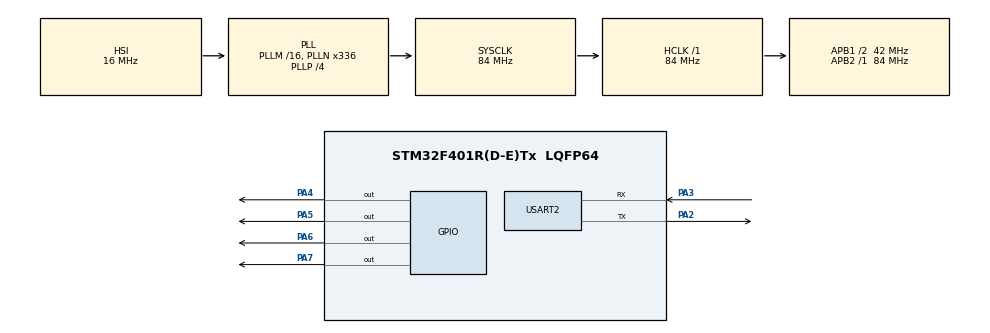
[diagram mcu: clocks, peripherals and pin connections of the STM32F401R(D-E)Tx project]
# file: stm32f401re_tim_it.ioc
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Mcu.Family=STM32F4
Mcu.Name=STM32F401R(D-E)Tx
Mcu.Package=LQFP64
NVIC.PriorityGroup=NVIC_PRIORITYGROUP_4
NVIC.TIM3_IRQn=true\:0\:0\:false\:false\:true\:true\:true\:true
NVIC.TIM4_IRQn=true\:0\:0\:false\:false\:true\:true\:true\:true
NVIC.TIM5_IRQn=true\:0\:0\:false\:false\:true\:true\:true\:true
PA2.Mode=Asynchronous
PA2.Signal=USART2_TX
PA3.Mode=Asynchronous
PA3.Signal=USART2_RX
PA4.Signal=GPIO_Output
PA5.Signal=GPIO_Output
PA6.Signal=GPIO_Output
PA7.Signal=GPIO_Output
ProjectManager.HeapSize=0x200
ProjectManager.StackSize=0x400
ProjectManager.TargetToolchain=STM32CubeIDE
RCC.48MHZClocksFreq_Value=48000000
RCC.AHBFreq_Value=84000000
RCC.APB1CLKDivider=RCC_HCLK_DIV2
RCC.APB1Freq_Value=42000000
RCC.APB1TimFreq_Value=84000000
RCC.APB2Freq_Value=84000000
RCC.APB2TimFreq_Value=84000000
RCC.CortexFreq_Value=84000000
RCC.HCLKFreq_Value=84000000
RCC.HSE_VALUE=8000000
RCC.HSI_VALUE=16000000
RCC.LSE_VALUE=32768
RCC.PLLN=336
RCC.PLLP=RCC_PLLP_DIV4
RCC.PLLQ=7
RCC.SYSCLKFreq_VALUE=84000000
RCC.SYSCLKSource=RCC_SYSCLKSOURCE_PLLCLK
RCC.VCOOutputFreq_Value=336000000
TIM3.Period=2000-1
TIM3.Prescaler=8400
TIM4.Period=5000-1
TIM4.Prescaler=8400-1
TIM5.Period=8000-1
TIM5.Prescaler=8400-1
USART2.VirtualMode=VM_ASYNC
VP_TIM3_VS_ClockSourceINT.Mode=Internal
VP_TIM4_VS_ClockSourceINT.Mode=Internal
VP_TIM5_VS_ClockSourceINT.Mode=Internal
board=NUCLEO-F401RE

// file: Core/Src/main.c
/* USER CODE BEGIN Header */
/**
  ******************************************************************************
  * @file           : main.c
  * @brief          : Main program body
  ******************************************************************************
  * @attention
  *
  * Copyright (c) 2025 STMicroelectronics.
  * All rights reserved.
  *
  * This software is licensed under terms that can be found in the LICENSE file
  * in the root directory of this software component.
  * If no LICENSE file comes with this software, it is provided AS-IS.
  *
  ******************************************************************************
  */
/* USER CODE END Header */
#include "main.h"

TIM_HandleTypeDef htim3;
TIM_HandleTypeDef htim4;
TIM_HandleTypeDef htim5;

UART_HandleTypeDef huart2;

void SystemClock_Config(void);
static void MX_GPIO_Init(void);
static void MX_TIM3_Init(void);
static void MX_TIM4_Init(void);
static void MX_TIM5_Init(void);
static void MX_USART2_UART_Init(void);

int main(void)
{

  /* MCU Configuration--------------------------------------------------------*/

  /* Reset of all peripherals, Initializes the Flash interface and the Systick. */
  HAL_Init();

  /* Configure the system clock */
  SystemClock_Config();

  /* Initialize all configured peripherals */
  MX_GPIO_Init();
  MX_TIM3_Init();
  MX_TIM4_Init();
  MX_TIM5_Init();
  MX_USART2_UART_Init();
  /* USER CODE BEGIN 2 */
  HAL_TIM_Base_Start_IT(&htim3);
  HAL_TIM_Base_Start_IT(&htim4);
  HAL_TIM_Base_Start_IT(&htim5);

  /* USER CODE END 2 */
HAL_UART_Transmit(&huart2, "DEVICE ON\n",20,20);
  /* Infinite loop */
  while (1)
  {
	//  HAL_UART_Transmit(&huart2, "DEVICE ON\n",20,20);

  }
}

void SystemClock_Config(void)
{
  RCC_OscInitTypeDef RCC_OscInitStruct = {0};
  RCC_ClkInitTypeDef RCC_ClkInitStruct = {0};

  /** Configure the main internal regulator output voltage
  */
  __HAL_RCC_PWR_CLK_ENABLE();
  __HAL_PWR_VOLTAGESCALING_CONFIG(PWR_REGULATOR_VOLTAGE_SCALE2);

  /** Initializes the RCC Oscillators according to the specified parameters
  * in the RCC_OscInitTypeDef structure.
  */
  RCC_OscInitStruct.OscillatorType = RCC_OSCILLATORTYPE_HSI;
  RCC_OscInitStruct.HSIState = RCC_HSI_ON;
  RCC_OscInitStruct.HSICalibrationValue = RCC_HSICALIBRATION_DEFAULT;
  RCC_OscInitStruct.PLL.PLLState = RCC_PLL_ON;
  RCC_OscInitStruct.PLL.PLLSource = RCC_PLLSOURCE_HSI;
  RCC_OscInitStruct.PLL.PLLM = 16;
  RCC_OscInitStruct.PLL.PLLN = 336;
  RCC_OscInitStruct.PLL.PLLP = RCC_PLLP_DIV4;
  RCC_OscInitStruct.PLL.PLLQ = 7;
  if (HAL_RCC_OscConfig(&RCC_OscInitStruct) != HAL_OK)
  {
    Error_Handler();
  }

  /** Initializes the CPU, AHB and APB buses clocks
  */
  RCC_ClkInitStruct.ClockType = RCC_CLOCKTYPE_HCLK|RCC_CLOCKTYPE_SYSCLK
                              |RCC_CLOCKTYPE_PCLK1|RCC_CLOCKTYPE_PCLK2;
  RCC_ClkInitStruct.SYSCLKSource = RCC_SYSCLKSOURCE_PLLCLK;
  RCC_ClkInitStruct.AHBCLKDivider = RCC_SYSCLK_DIV1;
  RCC_ClkInitStruct.APB1CLKDivider = RCC_HCLK_DIV2;
  RCC_ClkInitStruct.APB2CLKDivider = RCC_HCLK_DIV1;

  if (HAL_RCC_ClockConfig(&RCC_ClkInitStruct, FLASH_LATENCY_2) != HAL_OK)
  {
    Error_Handler();
  }
}

static void MX_TIM3_Init(void)
{

  TIM_ClockConfigTypeDef sClockSourceConfig = {0};
  TIM_MasterConfigTypeDef sMasterConfig = {0};

  htim3.Instance = TIM3;
  htim3.Init.Prescaler = 8400-1;
  htim3.Init.CounterMode = TIM_COUNTERMODE_UP;
  htim3.Init.Period = 2000-1;
  htim3.Init.ClockDivision = TIM_CLOCKDIVISION_DIV1;
  htim3.Init.AutoReloadPreload = TIM_AUTORELOAD_PRELOAD_DISABLE;
  if (HAL_TIM_Base_Init(&htim3) != HAL_OK)
  {
    Error_Handler();
  }
  sClockSourceConfig.ClockSource = TIM_CLOCKSOURCE_INTERNAL;
  if (HAL_TIM_ConfigClockSource(&htim3, &sClockSourceConfig) != HAL_OK)
  {
    Error_Handler();
  }
  sMasterConfig.MasterOutputTrigger = TIM_TRGO_RESET;
  sMasterConfig.MasterSlaveMode = TIM_MASTERSLAVEMODE_DISABLE;
  if (HAL_TIMEx_MasterConfigSynchronization(&htim3, &sMasterConfig) != HAL_OK)
  {
    Error_Handler();
  }

}

static void MX_TIM4_Init(void)
{

  TIM_ClockConfigTypeDef sClockSourceConfig = {0};
  TIM_MasterConfigTypeDef sMasterConfig = {0};

  htim4.Instance = TIM4;
  htim4.Init.Prescaler = 8400-1;
  htim4.Init.CounterMode = TIM_COUNTERMODE_UP;
  htim4.Init.Period = 5000-1;
  htim4.Init.ClockDivision = TIM_CLOCKDIVISION_DIV1;
  htim4.Init.AutoReloadPreload = TIM_AUTORELOAD_PRELOAD_DISABLE;
  if (HAL_TIM_Base_Init(&htim4) != HAL_OK)
  {
    Error_Handler();
  }
  sClockSourceConfig.ClockSource = TIM_CLOCKSOURCE_INTERNAL;
  if (HAL_TIM_ConfigClockSource(&htim4, &sClockSourceConfig) != HAL_OK)
  {
    Error_Handler();
  }
  sMasterConfig.MasterOutputTrigger = TIM_TRGO_RESET;
  sMasterConfig.MasterSlaveMode = TIM_MASTERSLAVEMODE_DISABLE;
  if (HAL_TIMEx_MasterConfigSynchronization(&htim4, &sMasterConfig) != HAL_OK)
  {
    Error_Handler();
  }

}

static void MX_TIM5_Init(void)
{

  TIM_ClockConfigTypeDef sClockSourceConfig = {0};
  TIM_MasterConfigTypeDef sMasterConfig = {0};

  htim5.Instance = TIM5;
  htim5.Init.Prescaler = 8400-1;
  htim5.Init.CounterMode = TIM_COUNTERMODE_UP;
  htim5.Init.Period = 8000-1;
  htim5.Init.ClockDivision = TIM_CLOCKDIVISION_DIV1;
  htim5.Init.AutoReloadPreload = TIM_AUTORELOAD_PRELOAD_DISABLE;
  if (HAL_TIM_Base_Init(&htim5) != HAL_OK)
  {
    Error_Handler();
  }
  sClockSourceConfig.ClockSource = TIM_CLOCKSOURCE_INTERNAL;
  if (HAL_TIM_ConfigClockSource(&htim5, &sClockSourceConfig) != HAL_OK)
  {
    Error_Handler();
  }
  sMasterConfig.MasterOutputTrigger = TIM_TRGO_RESET;
  sMasterConfig.MasterSlaveMode = TIM_MASTERSLAVEMODE_DISABLE;
  if (HAL_TIMEx_MasterConfigSynchronization(&htim5, &sMasterConfig) != HAL_OK)
  {
    Error_Handler();
  }

}

static void MX_USART2_UART_Init(void)
{

  huart2.Instance = USART2;
  huart2.Init.BaudRate = 115200;
  huart2.Init.WordLength = UART_WORDLENGTH_8B;
  huart2.Init.StopBits = UART_STOPBITS_1;
  huart2.Init.Parity = UART_PARITY_NONE;
  huart2.Init.Mode = UART_MODE_TX_RX;
  huart2.Init.HwFlowCtl = UART_HWCONTROL_NONE;
  huart2.Init.OverSampling = UART_OVERSAMPLING_16;
  if (HAL_UART_Init(&huart2) != HAL_OK)
  {
    Error_Handler();
  }

}

static void MX_GPIO_Init(void)
{
  GPIO_InitTypeDef GPIO_InitStruct = {0};

  /* GPIO Ports Clock Enable */
  __HAL_RCC_GPIOA_CLK_ENABLE();

  /*Configure GPIO pin Output Level */
  HAL_GPIO_WritePin(GPIOA, GPIO_PIN_4|GPIO_PIN_5|GPIO_PIN_6|GPIO_PIN_7, GPIO_PIN_RESET);

  /*Configure GPIO pins : PA4 PA5 PA6 PA7 */
  GPIO_InitStruct.Pin = GPIO_PIN_4|GPIO_PIN_5|GPIO_PIN_6|GPIO_PIN_7;
  GPIO_InitStruct.Mode = GPIO_MODE_OUTPUT_PP;
  GPIO_InitStruct.Pull = GPIO_NOPULL;
  GPIO_InitStruct.Speed = GPIO_SPEED_FREQ_LOW;
  HAL_GPIO_Init(GPIOA, &GPIO_InitStruct);

}

/* USER CODE BEGIN 4 */
void HAL_TIM_PeriodElapsedCallback(TIM_HandleTypeDef *htim)
{
  /* Prevent unused argument(s) compilation warning */
  UNUSED(htim);

  /* NOTE : This function should not be modified, when the callback is needed,
            the HAL_TIM_PeriodElapsedCallback could be implemented in the user file
   */

  if (htim->Instance == TIM3)

  {
	  HAL_GPIO_TogglePin(GPIOA, GPIO_PIN_5);
	  HAL_UART_Transmit(&huart2, "TIM1 \n",7,20);
  }

  else if (htim->Instance == TIM4)
  {
	  HAL_GPIO_TogglePin(GPIOA, GPIO_PIN_6);
	  HAL_UART_Transmit(&huart2, "TIM2 \n",7,20);
  }

  else if (htim->Instance == TIM5)
  {
	  HAL_GPIO_TogglePin(GPIOA,GPIO_PIN_7);
	  HAL_UART_Transmit(&huart2, "TIM3 \n",7,20);
  }
}

/* USER CODE END 4 */

void Error_Handler(void)
{
  __disable_irq();
  while (1)
  {
  }
}
